# MB9BF56xx register map
File version: 1.0
CPU: 
Registers are 8-bit, read-write, reset 0x0 unless marked. A register's access mark holds for its fields unless they carry their own. Offsets are from the block's base; [hi:lo] are bit positions; {n}, {i} and the like mark numbered series.

## MFT0 — peripheral MFT0
Base 0x40020000
Same registers: MFT1 0x40021000, MFT2 0x40022000
0x102 OCU_OCCP0 16-bit
{0x102+4i} OCU_OCCP{i} 32-bit reset not defined (i=1..5)
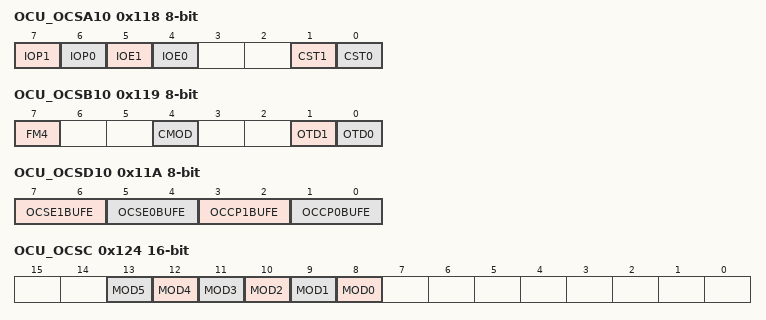
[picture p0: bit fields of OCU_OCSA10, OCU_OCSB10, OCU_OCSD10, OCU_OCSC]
0x118 OCU_OCSA10
  [7] IOP1, [6] IOP0, [5] IOE1, [4] IOE0, [1] CST1, [0] CST0
0x119 OCU_OCSB10
  [7] FM4, [4] CMOD, [1] OTD1, [0] OTD0
0x11A OCU_OCSD10
  [7:6] OCSE1BUFE, [5:4] OCSE0BUFE, [3:2] OCCP1BUFE, [1:0] OCCP0BUFE
0x11C OCU_OCSA32 32-bit reset not defined
0x11D OCU_OCSB32 32-bit reset not defined
0x11E OCU_OCSD32 32-bit reset not defined
0x120 OCU_OCSA54 32-bit reset not defined
0x121 OCU_OCSB54 32-bit reset not defined
0x122 OCU_OCSD54 32-bit reset not defined
0x124 OCU_OCSC 16-bit
  [n+8] MOD{n} (n=0..5)
0x128 OCU_OCSE0
  [7:0] OCSE
0x12C OCU_OCSE1 16-bit
  [15:0] OCSE
{0x128+4i} OCU_OCSE{i} 32-bit reset not defined (i=2..5)
0x142 FRT_TCCP0 16-bit reset 0xFFFF
0x146 FRT_TCDT0 16-bit
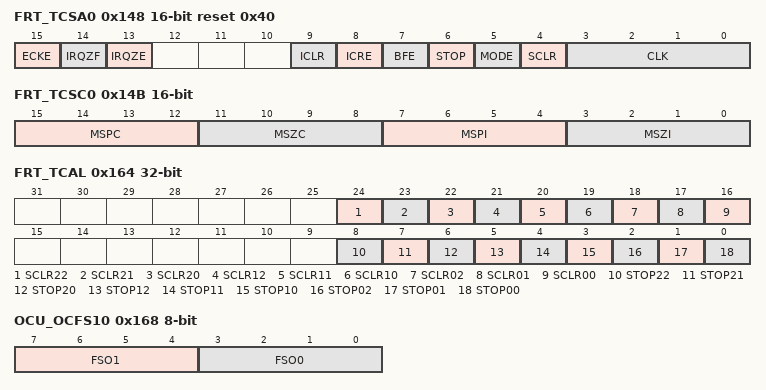
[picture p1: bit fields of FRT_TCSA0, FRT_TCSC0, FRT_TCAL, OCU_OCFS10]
0x148 FRT_TCSA0 16-bit reset 0x40
  [15] ECKE, [14] IRQZF, [13] IRQZE, [9] ICLR, [8] ICRE, [7] BFE, [6] STOP, [5] MODE, [4] SCLR wo, [3:0] CLK
0x14B FRT_TCSC0 16-bit
  [15:12] MSPC ro, [11:8] MSZC ro, [7:4] MSPI, [3:0] MSZI
0x14E FRT_TCCP1 32-bit reset not defined
0x152 FRT_TCDT1 32-bit reset not defined
0x154 FRT_TCSA1 32-bit reset not defined
0x156 FRT_TCSC1 32-bit reset not defined
0x15A FRT_TCCP2 32-bit reset not defined
0x15E FRT_TCDT2 32-bit reset not defined
0x160 FRT_TCSA2 32-bit reset not defined
0x162 FRT_TCSC2 32-bit reset not defined
0x164 FRT_TCAL 32-bit (reset mask 0xFFFF)
  [24] SCLR22 wo, [23] SCLR21 wo, [22] SCLR20 wo, [21] SCLR12 wo, [20] SCLR11 wo, [19] SCLR10 wo, [18] SCLR02 wo, [17] SCLR01 wo, [16] SCLR00 wo, [8] STOP22, [7] STOP21, [6] STOP20, [5] STOP12, [4] STOP11, [3] STOP10, [2] STOP02, [1] STOP01, [0] STOP00
0x168 OCU_OCFS10
  [7:4] FSO1, [3:0] FSO0
0x169 OCU_OCFS32 32-bit reset not defined
0x16A OCU_OCFS54 32-bit reset not defined
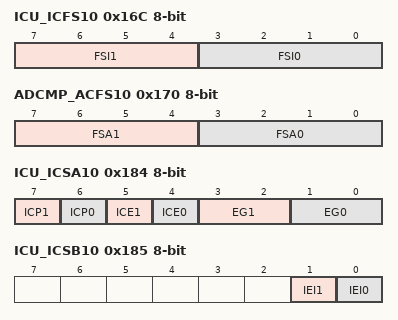
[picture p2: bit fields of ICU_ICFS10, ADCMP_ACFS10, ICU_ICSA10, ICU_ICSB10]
0x16C ICU_ICFS10
  [7:4] FSI1, [3:0] FSI0
0x16D ICU_ICFS32 32-bit reset not defined
0x170 ADCMP_ACFS10
  [7:4] FSA1, [3:0] FSA0
0x171 ADCMP_ACFS32 32-bit reset not defined
0x172 ADCMP_ACFS54 32-bit reset not defined
0x176 ICU_ICCP0 16-bit ro reset not defined
{0x176+4i} ICU_ICCP{i} 32-bit reset not defined (i=1..3)
0x184 ICU_ICSA10
  [7] ICP1, [6] ICP0, [5] ICE1, [4] ICE0, [3:2] EG1, [1:0] EG0
0x185 ICU_ICSB10 ro
  [1] IEI1, [0] IEI0
0x188 ICU_ICSA32 32-bit reset not defined
0x189 ICU_ICSB32 32-bit reset not defined
0x18E WFG_WFTF10 16-bit
0x190 WFG_WFTA10
0x192 WFG_WFTB10
0x196 WFG_WFTF32 16-bit
0x198 WFG_WFTA32
0x19A WFG_WFTB32
0x19E WFG_WFTF54 16-bit
0x1A0 WFG_WFTA54
0x1A2 WFG_WFTB54
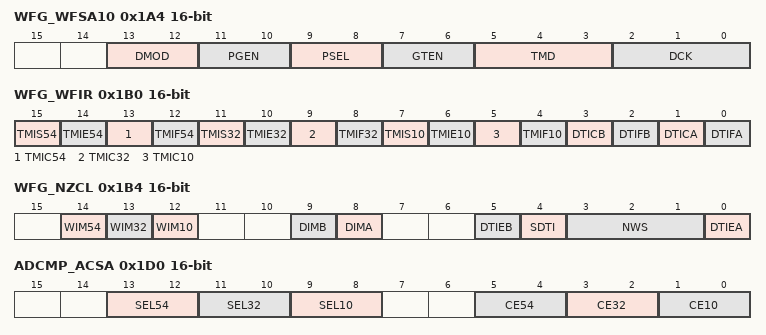
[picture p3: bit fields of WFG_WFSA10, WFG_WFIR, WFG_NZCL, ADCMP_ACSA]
0x1A4 WFG_WFSA10 16-bit
  [13:12] DMOD, [11:10] PGEN, [9:8] PSEL, [7:6] GTEN, [5:3] TMD, [2:0] DCK
0x1A8 WFG_WFSA32 32-bit reset not defined
0x1AC WFG_WFSA54 32-bit reset not defined
0x1B0 WFG_WFIR 16-bit
  [15] TMIS54 wo, [14] TMIE54, [13] TMIC54 wo, [12] TMIF54 ro, [11] TMIS32 wo, [10] TMIE32, [9] TMIC32 wo, [8] TMIF32 ro, [7] TMIS10 wo, [6] TMIE10, [5] TMIC10 wo, [4] TMIF10 ro, [3] DTICB wo, [2] DTIFB ro, [1] DTICA wo, [0] DTIFA ro
0x1B4 WFG_NZCL 16-bit
  [14] WIM54, [13] WIM32, [12] WIM10, [9] DIMB, [8] DIMA, [5] DTIEB, [4] SDTI wo, [3:1] NWS, [0] DTIEA
0x1BA ADCMP_ACMP0 16-bit
  [15:0] ACMP
{0x1BA+4i} ADCMP_ACMP{i} 32-bit reset not defined (i=1..5)
0x1D0 ADCMP_ACSA 16-bit
  [13:12] SEL54, [11:10] SEL32, [9:8] SEL10, [5:4] CE54, [3:2] CE32, [1:0] CE10
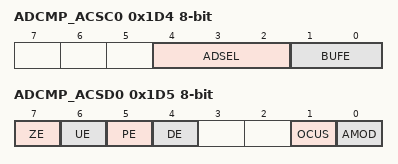
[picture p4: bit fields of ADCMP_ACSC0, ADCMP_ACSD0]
0x1D4 ADCMP_ACSC0
  [4:2] ADSEL, [1:0] BUFE
0x1D5 ADCMP_ACSD0
  [7] ZE, [6] UE, [5] PE, [4] DE, [1] OCUS, [0] AMOD
{0x1D4+4i} ADCMP_ACSC{i} 32-bit reset not defined (i=1..5)
{0x1D5+4i} ADCMP_ACSD{i} 32-bit reset not defined (i=1..5)

## MFT_PPG — peripheral MFT_PPG
Base 0x40024000
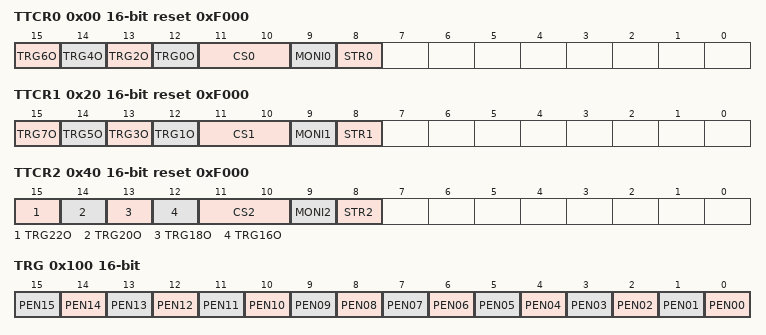
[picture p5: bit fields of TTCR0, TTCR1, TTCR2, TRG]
0x00 TTCR0 16-bit reset 0xF000
  [15] TRG6O, [14] TRG4O, [13] TRG2O, [12] TRG0O, [11:10] CS0, [9] MONI0 ro, [8] STR0
0x08 COMP0 16-bit (reset mask 0xFF00)
0x0C COMP2
0x10 COMP4 32-bit reset not defined
0x14 COMP6 32-bit reset not defined
0x20 TTCR1 16-bit reset 0xF000
  [15] TRG7O, [14] TRG5O, [13] TRG3O, [12] TRG1O, [11:10] CS1, [9] MONI1 ro, [8] STR1
0x28 COMP1 32-bit reset not defined
0x2C COMP3 32-bit reset not defined
0x30 COMP5 32-bit reset not defined
0x34 COMP7 32-bit reset not defined
0x40 TTCR2 16-bit reset 0xF000
  [15] TRG22O, [14] TRG20O, [13] TRG18O, [12] TRG16O, [11:10] CS2, [9] MONI2 ro, [8] STR2
0x48 COMP8 32-bit reset not defined
0x4C COMP10 32-bit reset not defined
0x50 COMP12 32-bit reset not defined
0x54 COMP14 32-bit reset not defined
0x100 TRG 16-bit
  [n] PEN{n:02} (n=0..15)
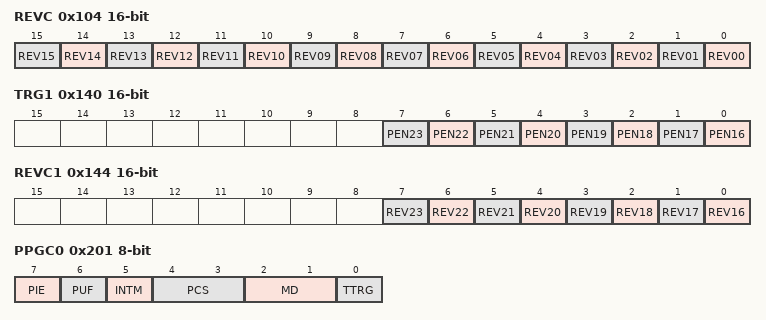
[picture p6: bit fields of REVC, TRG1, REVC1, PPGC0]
0x104 REVC 16-bit
  [n] REV{n:02} (n=0..15)
0x140 TRG1 16-bit
  [n-16] PEN{n} (n=16..23)
0x144 REVC1 16-bit
  [n-16] REV{n} (n=16..23)
0x200 PPGC1 32-bit reset not defined
0x201 PPGC0
  [7] PIE, [6] PUF, [5] INTM, [4:3] PCS, [2:1] MD, [0] TTRG
0x204 PPGC3 32-bit reset not defined
0x205 PPGC2 32-bit reset not defined
0x208 PRLL0 reset not defined
  [7:0] PRLL
0x209 PRLH0 reset not defined
  [7:0] PRLH
{0x208+4i} PRLL{i} 32-bit reset not defined (i=1..3)
{0x209+4i} PRLH{i} 32-bit reset not defined (i=1..3)
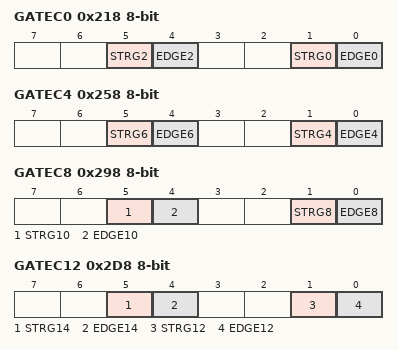
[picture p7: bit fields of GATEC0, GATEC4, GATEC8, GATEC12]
0x218 GATEC0
  [5] STRG2, [4] EDGE2, [1] STRG0, [0] EDGE0
0x240 PPGC5 32-bit reset not defined
0x241 PPGC4 32-bit reset not defined
0x244 PPGC7 32-bit reset not defined
0x245 PPGC6 32-bit reset not defined
{0x238+4i} PRLL{i} 32-bit reset not defined (i=4..7)
{0x239+4i} PRLH{i} 32-bit reset not defined (i=4..7)
0x258 GATEC4
  [5] STRG6, [4] EDGE6, [1] STRG4, [0] EDGE4
0x280 PPGC9 32-bit reset not defined
0x281 PPGC8 32-bit reset not defined
0x284 PPGC11 32-bit reset not defined
0x285 PPGC10 32-bit reset not defined
{0x268+4i} PRLL{i} 32-bit reset not defined (i=8..11)
{0x269+4i} PRLH{i} 32-bit reset not defined (i=8..11)
0x298 GATEC8
  [5] STRG10, [4] EDGE10, [1] STRG8, [0] EDGE8
0x2C0 PPGC13 32-bit reset not defined
0x2C1 PPGC12 32-bit reset not defined
0x2C4 PPGC15 32-bit reset not defined
0x2C5 PPGC14 32-bit reset not defined
{0x298+4i} PRLL{i} 32-bit reset not defined (i=12..15)
{0x299+4i} PRLH{i} 32-bit reset not defined (i=12..15)
0x2D8 GATEC12
  [5] STRG14, [4] EDGE14, [1] STRG12, [0] EDGE12
0x300 PPGC17 32-bit reset not defined
0x301 PPGC16 32-bit reset not defined
0x304 PPGC19 32-bit reset not defined
0x305 PPGC18 32-bit reset not defined
{0x2C8+4i} PRLL{i} 32-bit reset not defined (i=16..19)
{0x2C9+4i} PRLH{i} 32-bit reset not defined (i=16..19)
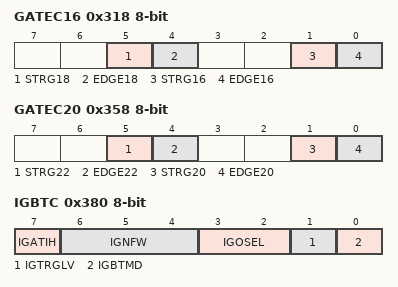
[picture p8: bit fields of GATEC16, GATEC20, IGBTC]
0x318 GATEC16
  [5] STRG18, [4] EDGE18, [1] STRG16, [0] EDGE16
0x340 PPGC21 32-bit reset not defined
0x341 PPGC20 32-bit reset not defined
0x344 PPGC23 32-bit reset not defined
0x345 PPGC22 32-bit reset not defined
{0x2F8+4i} PRLL{i} 32-bit reset not defined (i=20..23)
{0x2F9+4i} PRLH{i} 32-bit reset not defined (i=20..23)
0x358 GATEC20
  [5] STRG22, [4] EDGE22, [1] STRG20, [0] EDGE20
0x380 IGBTC
  [7] IGATIH, [6:4] IGNFW, [3:2] IGOSEL, [1] IGTRGLV, [0] IGBTMD
